VERSION ""

NS_ :

BS_:

BU_: INTERCEPTOR EBCM NEO ADAS PCM EPS VSA SCM BDY XXX EPB

BO_ 57 XXX_1: 3 XXX
 SG_ COUNTER : 21|2@0+ (1,0) [0|15] "" NEO
 SG_ CHECKSUM : 19|4@0+ (1,0) [0|3] "" NEO

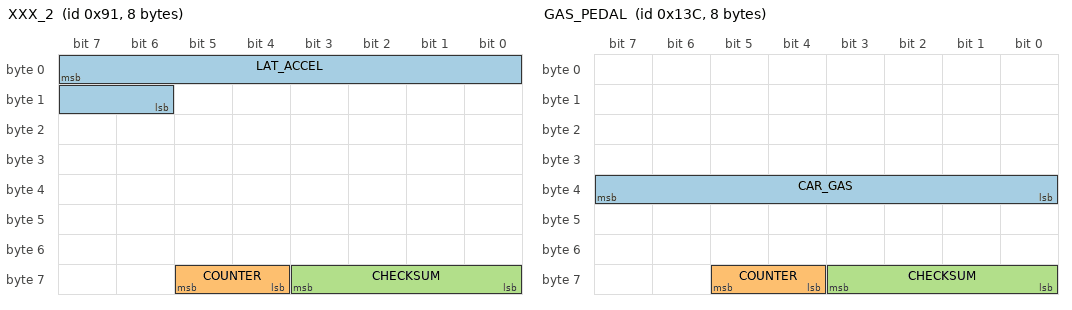
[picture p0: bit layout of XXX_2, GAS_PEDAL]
BO_ 145 XXX_2: 8 XXX
 SG_ LAT_ACCEL : 7|10@0+ (0.02,-512) [-20|20] "m/s2" NEO
 SG_ COUNTER : 61|2@0+ (1,0) [0|3] "" NEO
 SG_ CHECKSUM : 59|4@0+ (1,0) [0|15] "" NEO

BO_ 316 GAS_PEDAL: 8 PCM
 SG_ CAR_GAS : 39|8@0+ (1,0) [0|255] "" NEO
 SG_ COUNTER : 61|2@0+ (1,0) [0|3] "" NEO
 SG_ CHECKSUM : 59|4@0+ (1,0) [0|15] "" NEO

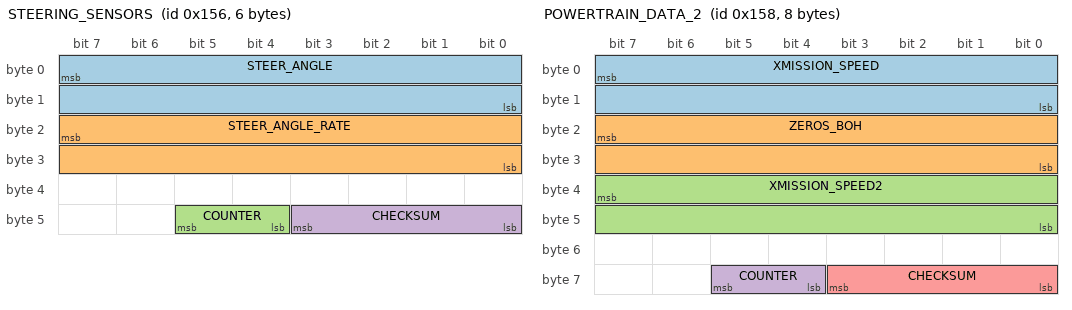
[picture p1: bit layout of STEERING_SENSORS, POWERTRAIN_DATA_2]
BO_ 342 STEERING_SENSORS: 6 EPS
 SG_ STEER_ANGLE : 7|16@0- (-0.1,0) [-500|500] "deg" NEO
 SG_ STEER_ANGLE_RATE : 23|16@0- (1,0) [-3000|3000] "deg/s" NEO
 SG_ COUNTER : 45|2@0+ (1,0) [0|3] "" NEO
 SG_ CHECKSUM : 43|4@0+ (1,0) [0|15] "" NEO

BO_ 344 POWERTRAIN_DATA_2: 8 PCM
 SG_ XMISSION_SPEED : 7|16@0+ (0.002759506,0) [0|70] "m/s" NEO
 SG_ ZEROS_BOH : 23|16@0+ (1,0) [0|15000] "" NEO
 SG_ XMISSION_SPEED2 : 39|16@0+ (0.002759506,0) [0|70] "m/s" NEO
 SG_ COUNTER : 61|2@0+ (1,0) [0|3] "" NEO
 SG_ CHECKSUM : 59|4@0+ (1,0) [0|15] "" NEO

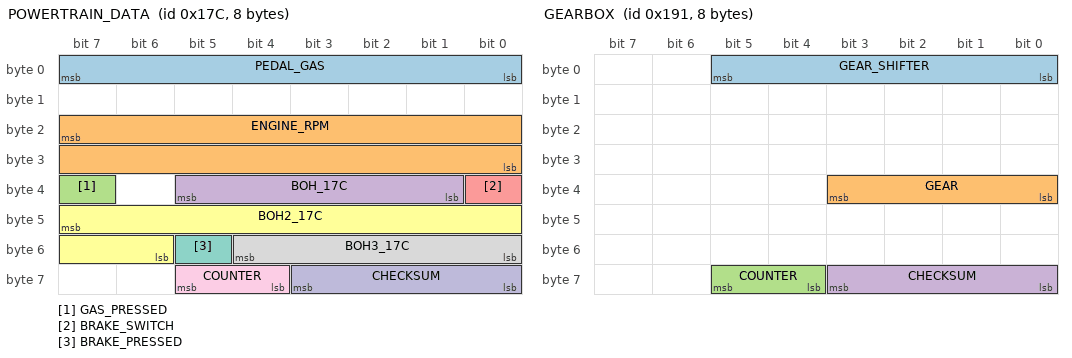
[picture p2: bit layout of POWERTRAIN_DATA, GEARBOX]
BO_ 380 POWERTRAIN_DATA: 8 PCM
 SG_ PEDAL_GAS : 7|8@0+ (1,0) [0|255] "" NEO
 SG_ ENGINE_RPM : 23|16@0+ (1,0) [0|15000] "rpm" NEO
 SG_ GAS_PRESSED : 39|1@0+ (1,0) [0|1] "" NEO
 SG_ BOH_17C : 37|5@0+ (1,0) [0|1] "rpm" NEO
 SG_ BRAKE_SWITCH : 32|1@0+ (1,0) [0|1] "rpm" NEO
 SG_ BOH2_17C : 47|10@0+ (1,0) [0|1] "rpm" NEO
 SG_ BRAKE_PRESSED : 53|1@0+ (1,0) [0|1] "" NEO
 SG_ BOH3_17C : 52|5@0+ (1,0) [0|1] "rpm" NEO
 SG_ COUNTER : 61|2@0+ (1,0) [0|3] "" NEO
 SG_ CHECKSUM : 59|4@0+ (1,0) [0|15] "" NEO

BO_ 398 XXX_3: 3 XXX
 SG_ COUNTER : 21|2@0+ (1,0) [0|15] "" XXX
 SG_ CHECKSUM : 19|4@0+ (1,0) [0|3] "" XXX

BO_ 401 GEARBOX: 8 PCM
 SG_ GEAR_SHIFTER : 5|6@0+ (1,0) [0|63] "" NEO
 SG_ GEAR : 35|4@0+ (1,0) [0|15] "" NEO
 SG_ COUNTER : 61|2@0+ (1,0) [0|3] "" NEO
 SG_ CHECKSUM : 59|4@0+ (1,0) [0|15] "" NEO

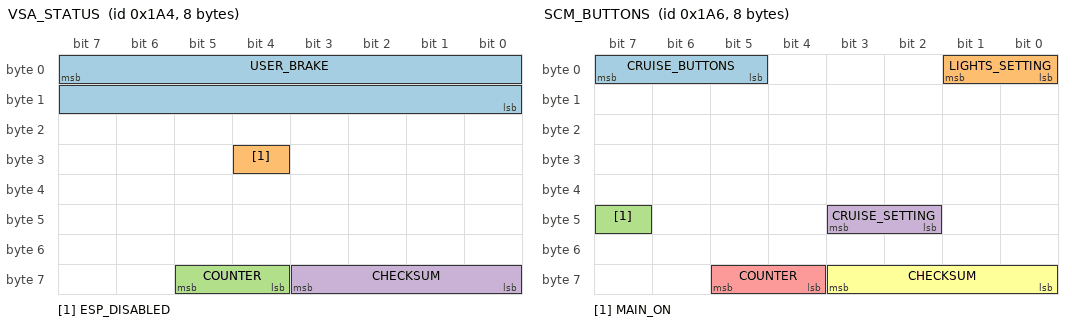
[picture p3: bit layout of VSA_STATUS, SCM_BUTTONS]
BO_ 420 VSA_STATUS: 8 VSA
 SG_ USER_BRAKE : 7|16@0+ (0.015625,-1.609375) [0|1000] "" NEO
 SG_ ESP_DISABLED : 28|1@0+ (1,0) [0|1] "" NEO
 SG_ COUNTER : 61|2@0+ (1,0) [0|3] "" NEO
 SG_ CHECKSUM : 59|4@0+ (1,0) [0|15] "" NEO

BO_ 422 SCM_BUTTONS: 8 SCM
 SG_ CRUISE_BUTTONS : 7|3@0+ (1,0) [0|7] "" NEO
 SG_ LIGHTS_SETTING : 1|2@0+ (1,0) [0|3] "" NEO
 SG_ MAIN_ON : 47|1@0+ (1,0) [0|1] "" NEO
 SG_ CRUISE_SETTING : 43|2@0+ (1,0) [0|3] "" NEO
 SG_ COUNTER : 61|2@0+ (1,0) [0|3] "" NEO
 SG_ CHECKSUM : 59|4@0+ (1,0) [0|15] "" NEO

BO_ 426 XXX_4: 8 VSA
 SG_ COUNTER : 61|2@0+ (1,0) [0|3] "" NEO
 SG_ CHECKSUM : 59|4@0+ (1,0) [0|15] "" NEO

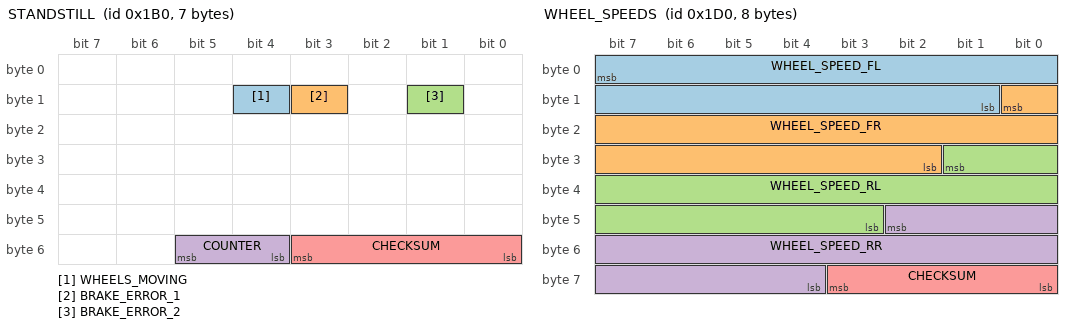
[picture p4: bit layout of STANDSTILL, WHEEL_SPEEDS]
BO_ 432 STANDSTILL: 7 VSA
 SG_ WHEELS_MOVING : 12|1@0+ (1,0) [0|1] "" NEO
 SG_ BRAKE_ERROR_1 : 11|1@0+ (1,0) [0|1] "" NEO
 SG_ BRAKE_ERROR_2 : 9|1@0+ (1,0) [0|1] "" NEO
 SG_ COUNTER : 53|2@0+ (1,0) [0|3] "" NEO
 SG_ CHECKSUM : 51|4@0+ (1,0) [0|15] "" NEO

BO_ 464 WHEEL_SPEEDS: 8 VSA
 SG_ WHEEL_SPEED_FL : 7|15@0+ (0.002759506,0) [0|70] "m/s" NEO
 SG_ WHEEL_SPEED_FR : 8|15@0+ (0.002759506,0) [0|70] "m/s" NEO
 SG_ WHEEL_SPEED_RL : 25|15@0+ (0.002759506,0) [0|70] "m/s" NEO
 SG_ WHEEL_SPEED_RR : 42|15@0+ (0.002759506,0) [0|70] "m/s" NEO
 SG_ CHECKSUM : 59|4@0+ (1,0) [0|15] "" NEO

BO_ 476 XXX_5: 4 XXX
 SG_ COUNTER : 29|2@0+ (1,0) [0|3] "" XXX
 SG_ CHECKSUM : 27|4@0+ (1,0) [0|15] "" XXX

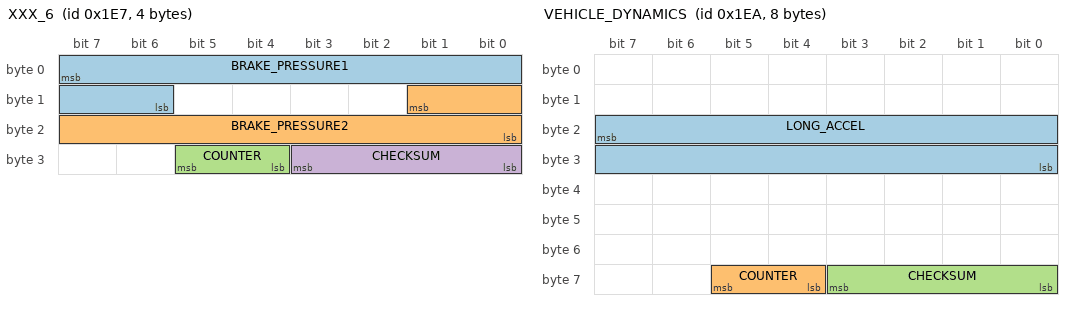
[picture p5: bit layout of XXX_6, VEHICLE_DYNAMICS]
BO_ 487 XXX_6: 4 VSA
 SG_ BRAKE_PRESSURE1 : 7|10@0+ (0.015625,-103) [0|1000] "" NEO
 SG_ BRAKE_PRESSURE2 : 9|10@0+ (0.015625,-103) [0|1000] "" NEO
 SG_ COUNTER : 29|2@0+ (1,0) [0|3] "" XXX
 SG_ CHECKSUM : 27|4@0+ (1,0) [0|15] "" XXX

BO_ 490 VEHICLE_DYNAMICS: 8 VSA
 SG_ LONG_ACCEL : 23|16@0- (0.0015384,0) [-20|20] "m/s2" NEO
 SG_ COUNTER : 61|2@0+ (1,0) [0|3] "" XXX
 SG_ CHECKSUM : 59|4@0+ (1,0) [0|15] "" XXX

BO_ 506 BRAKE_COMMAND: 8 ADAS
 SG_ COMPUTER_BRAKE : 7|10@0+ (0.003906248,0) [0|1023] "" EBCM
 SG_ ZEROS_BOH : 13|5@0+ (1,0) [0|1] "" EBCM
 SG_ COMPUTER_BRAKE_REQUEST : 8|1@0+ (1,0) [0|1] "" EBCM
 SG_ CRUISE_BOH2 : 23|3@0+ (1,0) [0|7] "" EBCM
 SG_ CRUISE_OVERRIDE : 20|1@0+ (1,0) [0|1] "" EBCM
 SG_ CRUISE_BOH3 : 19|1@0+ (1,0) [0|1] "" EBCM
 SG_ CRUISE_FAULT_CMD : 18|1@0+ (1,0) [0|1] "" EBCM
 SG_ CRUISE_CANCEL_CMD : 17|1@0+ (1,0) [0|1] "" EBCM
 SG_ COMPUTER_BRAKE_REQUEST_2 : 16|1@0+ (1,0) [0|1] "" EBCM
 SG_ SET_ME_0X80 : 31|8@0+ (1,0) [0|1] "" EBCM
 SG_ BRAKE_LIGHTS : 39|1@0+ (1,0) [0|1] "" EBCM
 SG_ CRUISE_STATES : 38|7@0+ (1,0) [0|127] "" EBCM
 SG_ CHIME : 47|3@0+ (1,0) [0|7] "" EBCM
 SG_ ZEROS_BOH6 : 44|1@0+ (1,0) [0|1] "" EBCM
 SG_ FCW : 43|1@0+ (1,0) [0|3] "" EBCM
 SG_ ZEROS_BOH3 : 42|2@0+ (1,0) [0|0] "" EBCM
 SG_ FCW2 : 40|1@0+ (1,0) [0|0] "" EBCM
 SG_ ZEROS_BOH4 : 55|8@0+ (1,0) [0|0] "" EBCM
 SG_ COUNTER : 61|2@0+ (1,0) [0|3] "" EBCM
 SG_ CHECKSUM : 59|4@0+ (1,0) [0|15] "" EBCM

BO_ 507 XXX_7: 1 XXX

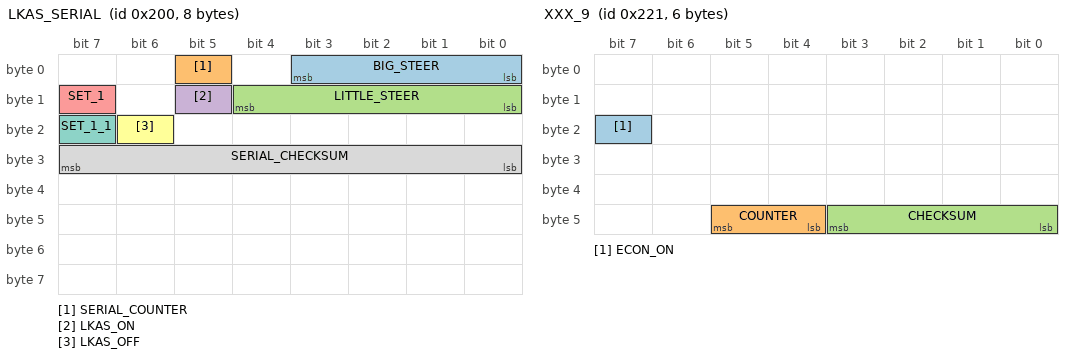
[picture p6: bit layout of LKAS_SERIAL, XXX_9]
BO_ 512 LKAS_SERIAL: 8 XXX
 SG_ BIG_STEER : 3|4@0- (1,0) [0|15] "" XXX
 SG_ SERIAL_COUNTER : 5|1@0+ (1,0) [0|1] "" XXX
 SG_ LITTLE_STEER : 12|5@0- (1,0) [0|31] "" XXX
 SG_ LKAS_ON : 13|1@0+ (1,0) [0|1] "" XXX
 SG_ SET_1 : 15|1@0+ (1,0) [0|1] "" XXX
 SG_ LKAS_OFF : 22|1@0+ (1,0) [0|1] "" XXX
 SG_ SET_1_1 : 23|1@0+ (1,0) [0|1] "" XXX
 SG_ SERIAL_CHECKSUM : 24|8@1+ (1,32) [0|255] "" XXX

BO_ 542 XXX_8: 7 XXX
 SG_ COUNTER : 53|2@0+ (1,0) [0|3] "" XXX
 SG_ CHECKSUM : 51|4@0+ (1,0) [0|15] "" XXX

BO_ 545 XXX_9: 6 SCM
 SG_ ECON_ON : 23|1@0+ (1,0) [0|1] "" XXX
 SG_ COUNTER : 45|2@0+ (1,0) [0|3] "" BDY
 SG_ CHECKSUM : 43|4@0+ (1,0) [0|15] "" BDY

BO_ 597 ROUGH_WHEEL_SPEED: 8 VSA
 SG_ WHEEL_SPEED_FL : 7|8@0+ (1,0) [0|255] "mph" NEO
 SG_ WHEEL_SPEED_FR : 15|8@0+ (1,0) [0|255] "mph" NEO
 SG_ WHEEL_SPEED_RL : 23|8@0+ (1,0) [0|255] "mph" NEO
 SG_ WHEEL_SPEED_RR : 31|8@0+ (1,0) [0|255] "mph" NEO
 SG_ SET_TO_X55 : 39|8@0+ (1,0) [0|255] "" XXX
 SG_ SET_TO_X55_2 : 47|8@0+ (1,0) [0|255] "" NEO
 SG_ LONG_COUNTER : 55|8@0+ (1,0) [0|255] "" XXX
 SG_ COUNTER : 61|2@0+ (1,0) [0|3] "" XXX
 SG_ CHECKSUM : 59|4@1+ (1,0) [0|15] "" XXX

BO_ 660 SCM_COMMANDS: 8 SCM
 SG_ RIGHT_BLINKER : 6|1@0+ (1,0) [0|1] "" NEO
 SG_ LEFT_BLINKER : 5|1@0+ (1,0) [0|1] "" NEO
 SG_ WIPERS_SPEED : 4|2@0+ (1,0) [0|3] "" NEO
 SG_ COUNTER : 61|2@0+ (1,0) [0|3] "" XXX
 SG_ CHECKSUM : 59|4@1+ (1,0) [0|15] "" XXX

BO_ 661 XXX_10: 4 XXX
 SG_ COUNTER : 29|2@0+ (1,0) [0|3] "" XXX
 SG_ CHECKSUM : 27|4@0+ (1,0) [0|15] "" XXX

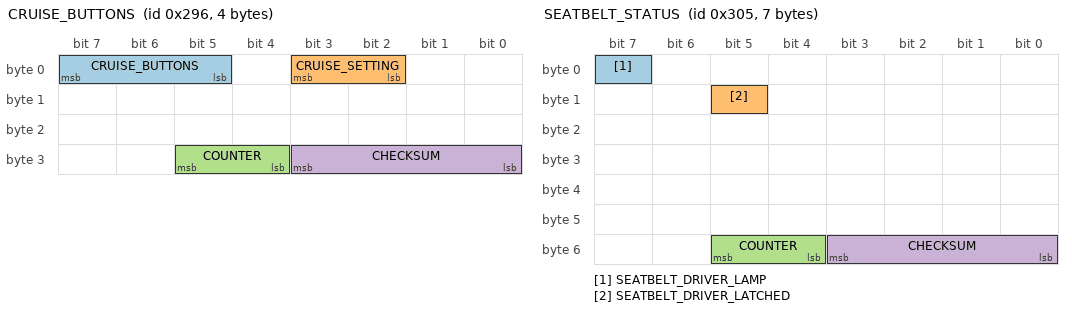
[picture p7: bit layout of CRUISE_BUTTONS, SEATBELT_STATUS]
BO_ 662 CRUISE_BUTTONS: 4 SCM
 SG_ CRUISE_BUTTONS : 7|3@0+ (1,0) [0|7] "" NEO
 SG_ CRUISE_SETTING : 3|2@0+ (1,0) [0|3] "" NEO
 SG_ COUNTER : 29|2@0+ (1,0) [0|3] "" XXX
 SG_ CHECKSUM : 27|4@0+ (1,0) [0|15] "" XXX

BO_ 773 SEATBELT_STATUS: 7 BDY
 SG_ SEATBELT_DRIVER_LAMP : 7|1@0+ (1,0) [0|1] "" NEO
 SG_ SEATBELT_DRIVER_LATCHED : 13|1@0+ (1,0) [0|1] "" NEO
 SG_ COUNTER : 53|2@0+ (1,0) [0|3] "" NEO
 SG_ CHECKSUM : 51|4@0+ (1,0) [0|15] "" NEO

BO_ 777 XXX_11: 8 XXX
 SG_ COUNTER : 61|2@0+ (1,0) [0|3] "" XXX
 SG_ CHECKSUM : 59|4@0+ (1,0) [0|15] "" XXX

BO_ 780 ACC_HUD: 8 ADAS
 SG_ PCM_SPEED : 7|16@0+ (0.002763889,0) [0|100] "m/s" BDY
 SG_ PCM_GAS : 23|7@0+ (1,0) [0|127] "" BDY
 SG_ ZEROS_BOH : 16|1@0+ (1,0) [0|255] "" BDY
 SG_ CRUISE_SPEED : 31|8@0+ (1,0) [0|255] "" BDY
 SG_ DTC_MODE : 39|1@0+ (1,0) [0|1] "" BDY
 SG_ BOH : 38|1@0+ (1,0) [0|1] "" BDY
 SG_ ACC_PROBLEM : 37|1@0+ (1,0) [0|1] "" BDY
 SG_ FCM_OFF : 36|1@0+ (1,0) [0|1] "" BDY
 SG_ BOH_2 : 35|1@0+ (1,0) [0|1] "" BDY
 SG_ FCM_PROBLEM : 34|1@0+ (1,0) [0|1] "" BDY
 SG_ RADAR_OBSTRUCTED : 33|1@0+ (1,0) [0|1] "" BDY
 SG_ ENABLE_MINI_CAR : 32|1@0+ (1,0) [0|1] "" BDY
 SG_ HUD_DISTANCE : 47|2@0+ (1,0) [0|3] "" BDY
 SG_ HUD_LEAD : 45|2@0+ (1,0) [0|3] "" BDY
 SG_ BOH_3 : 43|1@0+ (1,0) [0|3] "" BDY
 SG_ BOH_4 : 42|1@0+ (1,0) [0|3] "" BDY
 SG_ BOH_5 : 41|1@0+ (1,0) [0|3] "" BDY
 SG_ CRUISE_CONTROL_LABEL : 40|1@0+ (1,0) [0|3] "" BDY
 SG_ COUNTER : 61|2@0+ (1,0) [0|3] "" BDY
 SG_ CHECKSUM : 59|4@0+ (1,0) [0|15] "" BDY

BO_ 800 XXX_12: 8 XXX
 SG_ COUNTER : 61|2@0+ (1,0) [0|3] "" XXX
 SG_ CHECKSUM : 59|4@0+ (1,0) [0|15] "" XXX

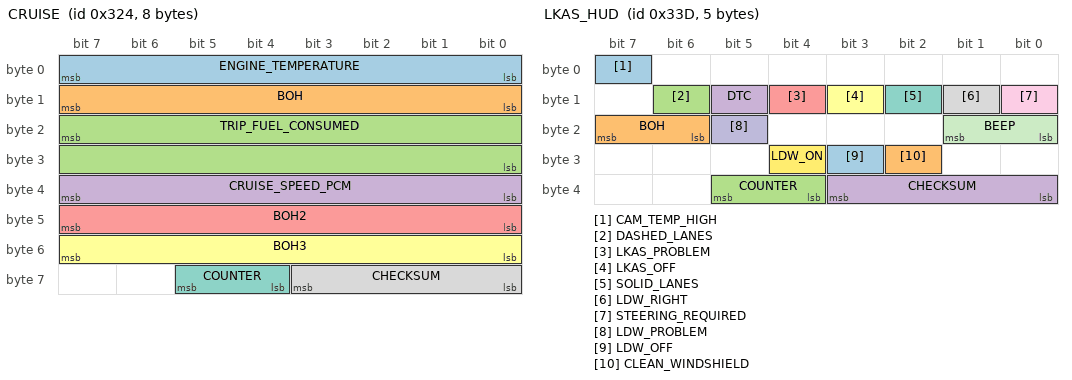
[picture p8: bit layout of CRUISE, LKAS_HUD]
BO_ 804 CRUISE: 8 PCM
 SG_ ENGINE_TEMPERATURE : 7|8@0+ (1,0) [0|255] "" NEO
 SG_ BOH : 15|8@0+ (1,0) [0|255] "" NEO
 SG_ TRIP_FUEL_CONSUMED : 23|16@0+ (1,0) [0|255] "" NEO
 SG_ CRUISE_SPEED_PCM : 39|8@0+ (1,0) [0|255] "" NEO
 SG_ BOH2 : 47|8@0- (1,0) [0|255] "" NEO
 SG_ BOH3 : 55|8@0+ (1,0) [0|255] "" NEO
 SG_ COUNTER : 61|2@0+ (1,0) [0|3] "" NEO
 SG_ CHECKSUM : 59|4@0+ (1,0) [0|15] "" NEO

BO_ 808 XXX_13: 8 XXX
 SG_ COUNTER : 61|2@0+ (1,0) [0|3] "" XXX
 SG_ CHECKSUM : 59|4@0+ (1,0) [0|15] "" XXX

BO_ 829 LKAS_HUD: 5 ADAS
 SG_ CAM_TEMP_HIGH : 7|1@0+ (1,0) [0|255] "" BDY
 SG_ BOH : 23|2@0+ (1,0) [0|4] "" BDY
 SG_ DASHED_LANES : 14|1@0+ (1,0) [0|1] "" BDY
 SG_ DTC : 13|1@0+ (1,0) [0|1] "" BDY
 SG_ LKAS_PROBLEM : 12|1@0+ (1,0) [0|1] "" BDY
 SG_ LKAS_OFF : 11|1@0+ (1,0) [0|1] "" BDY
 SG_ SOLID_LANES : 10|1@0+ (1,0) [0|1] "" BDY
 SG_ LDW_RIGHT : 9|1@0+ (1,0) [0|1] "" BDY
 SG_ STEERING_REQUIRED : 8|1@0+ (1,0) [0|1] "" BDY
 SG_ LDW_PROBLEM : 21|1@0+ (1,0) [0|1] "" BDY
 SG_ BEEP : 17|2@0+ (1,0) [0|1] "" BDY
 SG_ LDW_ON : 28|1@0+ (1,0) [0|1] "" BDY
 SG_ LDW_OFF : 27|1@0+ (1,0) [0|1] "" BDY
 SG_ CLEAN_WINDSHIELD : 26|1@0+ (1,0) [0|1] "" BDY
 SG_ COUNTER : 37|2@0+ (1,0) [0|3] "" BDY
 SG_ CHECKSUM : 35|4@0+ (1,0) [0|15] "" BDY

BO_ 871 XXX_14: 8 XXX
 SG_ COUNTER : 61|2@0+ (1,0) [0|3] "" XXX
 SG_ CHECKSUM : 59|4@0+ (1,0) [0|15] "" XXX

BO_ 882 XXX_15: 2 XXX
 SG_ COUNTER : 13|2@0+ (1,0) [0|3] "" XXX
 SG_ CHECKSUM : 11|4@0+ (1,0) [0|15] "" XXX

BO_ 884 XXX_16: 8 XXX
 SG_ COUNTER : 61|2@0+ (1,0) [0|3] "" XXX
 SG_ CHECKSUM : 59|4@0+ (1,0) [0|15] "" XXX

BO_ 891 XXX_17: 8 XXX
 SG_ COUNTER : 61|2@0+ (1,0) [0|3] "" XXX
 SG_ CHECKSUM : 59|4@0+ (1,0) [0|15] "" XXX

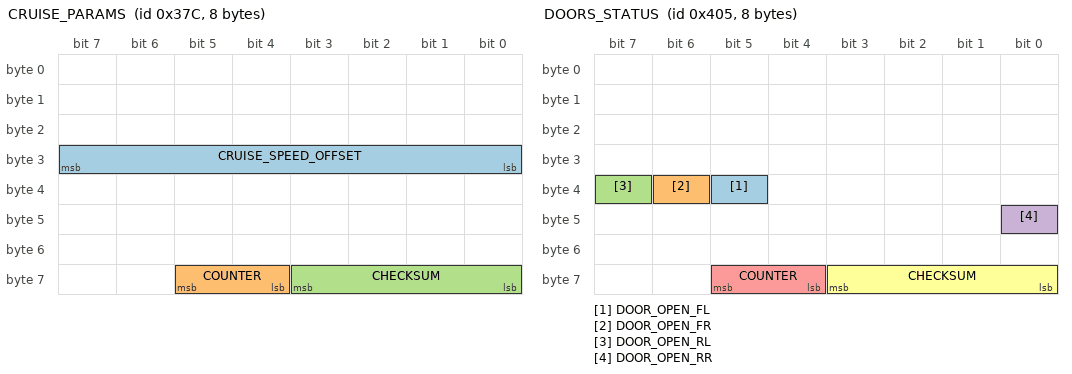
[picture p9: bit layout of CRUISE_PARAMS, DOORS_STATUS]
BO_ 892 CRUISE_PARAMS: 8 PCM
 SG_ CRUISE_SPEED_OFFSET : 31|8@0- (0.1,0) [-128|127] "kph" NEO
 SG_ COUNTER : 61|2@0+ (1,0) [0|3] "" XXX
 SG_ CHECKSUM : 59|4@0+ (1,0) [0|15] "" XXX

BO_ 918 XXX_18: 7 XXX
 SG_ COUNTER : 53|2@0+ (1,0) [0|3] "" XXX
 SG_ CHECKSUM : 51|4@0+ (1,0) [0|15] "" XXX

BO_ 923 XXX_19: 2 XXX
 SG_ COUNTER : 13|2@0+ (1,0) [0|3] "" XXX
 SG_ CHECKSUM : 11|4@0+ (1,0) [0|15] "" XXX

BO_ 927 ACC_HUD_2: 8 ADAS
 SG_ ZEROS_BOH : 7|17@0+ (1,0) [0|127] "" BDY
 SG_ APPLY_BRAKES_FOR_CANC : 23|1@0+ (1,0) [0|15] "" BDY
 SG_ ZEROS_BOH2 : 31|8@0+ (1,0) [0|127] "" BDY
 SG_ RESUME_INSTRUCTION : 21|1@0+ (1,0) [0|15] "" BDY
 SG_ ACC_ALERTS : 20|5@0+ (1,0) [0|15] "" BDY
 SG_ LEAD_SPEED : 39|9@0+ (1,0) [0|127] "" BDY
 SG_ LEAD_STATE : 46|3@0+ (1,0) [0|127] "" BDY
 SG_ LEAD_DISTANCE : 43|5@0+ (1,0) [0|31] "" BDY
 SG_ ZEROS_BOH3 : 54|7@0+ (1,0) [0|127] "" BDY
 SG_ COUNTER : 61|2@0+ (1,0) [0|3] "" XXX
 SG_ CHECKSUM : 59|4@0+ (1,0) [0|15] "" XXX

BO_ 929 XXX_20: 8 XXX
 SG_ COUNTER : 61|2@0+ (1,0) [0|3] "" XXX
 SG_ CHECKSUM : 59|4@0+ (1,0) [0|15] "" XXX

BO_ 983 XXX_21: 8 XXX
 SG_ COUNTER : 61|2@0+ (1,0) [0|3] "" XXX
 SG_ CHECKSUM : 59|4@0+ (1,0) [0|15] "" XXX

BO_ 985 XXX_22: 3 XXX
 SG_ COUNTER : 21|2@0+ (1,0) [0|15] "" XXX
 SG_ CHECKSUM : 19|4@0+ (1,0) [0|3] "" XXX

BO_ 1024 XXX_23: 5 XXX
 SG_ COUNTER : 37|2@0+ (1,0) [0|3] "" XXX
 SG_ CHECKSUM : 35|4@0+ (1,0) [0|15] "" XXX

BO_ 1027 XXX_24: 5 XXX
 SG_ COUNTER : 37|2@0+ (1,0) [0|3] "" XXX
 SG_ CHECKSUM : 35|4@0+ (1,0) [0|15] "" XXX

BO_ 1029 DOORS_STATUS: 8 BDY
 SG_ DOOR_OPEN_FL : 37|1@0+ (1,0) [0|1] "" NEO
 SG_ DOOR_OPEN_FR : 38|1@0+ (1,0) [0|1] "" NEO
 SG_ DOOR_OPEN_RL : 39|1@0+ (1,0) [0|1] "" NEO
 SG_ DOOR_OPEN_RR : 40|1@0+ (1,0) [0|1] "" NEO
 SG_ COUNTER : 61|2@0+ (1,0) [0|3] "" NEO
 SG_ CHECKSUM : 59|4@0+ (1,0) [0|15] "" NEO

BO_ 1036 XXX_25: 8 XXX
 SG_ COUNTER : 61|2@0+ (1,0) [0|3] "" XXX
 SG_ CHECKSUM : 59|4@0+ (1,0) [0|15] "" XXX

BO_ 1039 XXX_26: 8 XXX
 SG_ COUNTER : 61|2@0+ (1,0) [0|3] "" XXX
 SG_ CHECKSUM : 59|4@0+ (1,0) [0|15] "" XXX

BO_ 1057 XXX_27: 8 XXX
 SG_ COUNTER : 61|2@0+ (1,0) [0|3] "" XXX
 SG_ CHECKSUM : 59|4@0+ (1,0) [0|15] "" XXX

BO_ 1064 XXX_28: 7 XXX
 SG_ COUNTER : 53|2@0+ (1,0) [0|3] "" XXX
 SG_ CHECKSUM : 51|4@0+ (1,0) [0|15] "" XXX

BO_ 1088 XXX_29: 8 XXX
 SG_ COUNTER : 61|2@0+ (1,0) [0|3] "" XXX
 SG_ CHECKSUM : 59|4@0+ (1,0) [0|15] "" XXX

BO_ 1089 XXX_30: 8 XXX
 SG_ COUNTER : 61|2@0+ (1,0) [0|3] "" XXX
 SG_ CHECKSUM : 59|4@0+ (1,0) [0|15] "" XXX

BO_ 1108 XXX_31: 8 XXX
 SG_ COUNTER : 61|2@0+ (1,0) [0|3] "" XXX
 SG_ CHECKSUM : 59|4@0+ (1,0) [0|15] "" XXX

BO_ 1125 XXX_32: 8 XXX
 SG_ COUNTER : 61|2@0+ (1,0) [0|3] "" XXX
 SG_ CHECKSUM : 59|4@0+ (1,0) [0|15] "" XXX

BO_ 1296 XXX_33: 3 XXX
 SG_ COUNTER : 21|2@0+ (1,0) [0|15] "" XXX
 SG_ CHECKSUM : 19|4@0+ (1,0) [0|3] "" XXX

BO_ 1365 XXX_34: 5 XXX
 SG_ COUNTER : 37|2@0+ (1,0) [0|3] "" XXX
 SG_ CHECKSUM : 35|4@0+ (1,0) [0|15] "" XXX

BO_ 1424 XXX_35: 5 XXX
 SG_ COUNTER : 37|2@0+ (1,0) [0|3] "" XXX
 SG_ CHECKSUM : 35|4@0+ (1,0) [0|15] "" XXX

BO_ 1600 XXX_36: 5 XXX
 SG_ COUNTER : 37|2@0+ (1,0) [0|3] "" XXX
 SG_ CHECKSUM : 35|4@0+ (1,0) [0|15] "" XXX

BO_ 1601 XXX_37: 8 XXX
 SG_ COUNTER : 61|2@0+ (1,0) [0|3] "" XXX
 SG_ CHECKSUM : 59|4@0+ (1,0) [0|15] "" XXX

BO_ 1633 XXX_38: 8 XXX
 SG_ COUNTER : 61|2@0+ (1,0) [0|3] "" XXX
 SG_ CHECKSUM : 59|4@0+ (1,0) [0|15] "" XXX

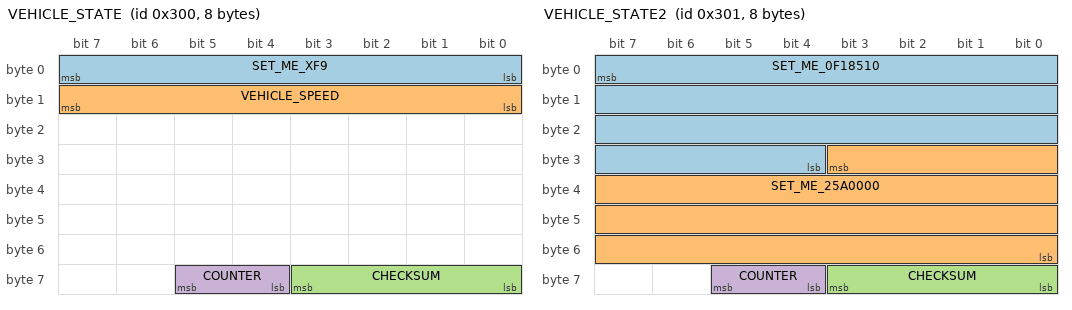
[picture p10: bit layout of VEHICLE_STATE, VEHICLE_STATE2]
BO_ 768 VEHICLE_STATE: 8 ADAS
 SG_ SET_ME_XF9 : 7|8@0+ (1,0) [0|255] "" Vector__XXX
 SG_ VEHICLE_SPEED : 15|8@0+ (1,0) [0|255] "kph" Vector__XXX
 SG_ CHECKSUM : 56|4@1+ (1,0) [0|15] "" XXX
 SG_ COUNTER : 61|2@0+ (1,0) [0|3] "" XXX

BO_ 769 VEHICLE_STATE2: 8 ADAS
 SG_ SET_ME_0F18510 : 7|28@0+ (1,0) [0|268435455] "" Vector__XXX
 SG_ SET_ME_25A0000 : 27|28@0+ (1,0) [0|268435455] "" Vector__XXX
 SG_ CHECKSUM : 56|4@1+ (1,0) [0|15] "" XXX
 SG_ COUNTER : 61|2@0+ (1,0) [0|3] "" XXX

BO_TX_BU_ 506 : NEO,ADAS;
BO_TX_BU_ 780 : NEO,ADAS;
BO_TX_BU_ 829 : NEO,ADAS;
BO_TX_BU_ 927 : NEO,ADAS;

CM_ "CHFFR_METRIC 342 STEER_ANGLE STEER_ANGLE 0.36 180; CHFFR_METRIC 380 ENGINE_RPM ENGINE_RPM 1 0; CHFFR_METRIC 804 ENGINE_TEMPERATURE ENGINE_TEMPERATURE 1 0";
